# ESP32C5_RADIO register map
Vendor: Espressif; Series: ESP32-C5; File version: 0.1
Registers are 32-bit, read-write, no defined reset value unless marked. A register's access mark holds for its fields unless they carry their own. Offsets are from the block's base; [hi:lo] are bit positions; {n}, {i} and the like mark numbered series.

## WIFI_MAC_TX_COMMON — Shared Wi-Fi CCA, timeout and completion state used by MAC transmit queues and the PHY-owned Wi-Fi CCA gate.
Base 0x600A4C5C
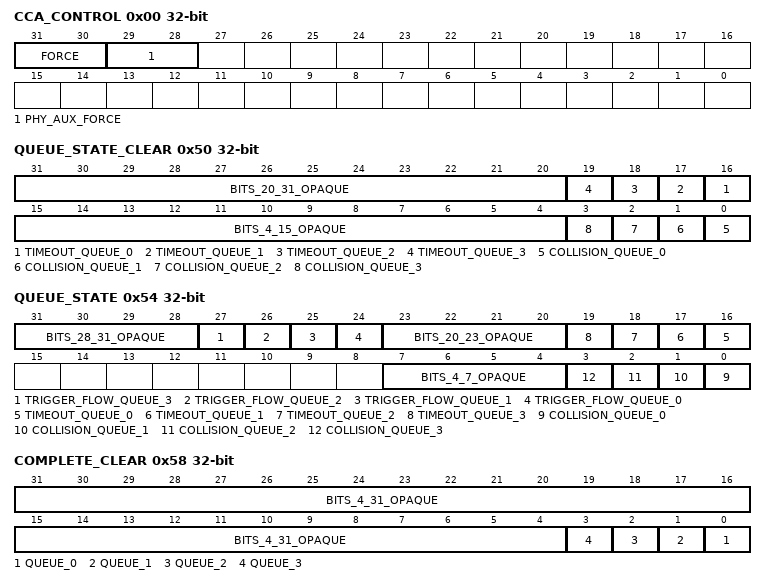
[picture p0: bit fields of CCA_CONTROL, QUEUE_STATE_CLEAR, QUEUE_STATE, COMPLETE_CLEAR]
0x00 CCA_CONTROL — Project-assigned name. Global Wi-Fi TX CCA control; complete PHY enable/disable leaves update the high two fields through separate fresh reads.
  [31:30] FORCE — Project-assigned name. Value three suppresses CCA while invalidating a timed-out queue. Complete libphy[phy_reg.o]::phy_disable_cca writes encoding two and complete libphy[phy_reg.o]::phy_enable_cca writes zero.
  [29:28] PHY_AUX_FORCE — Project-assigned name. Complete libphy[phy_reg.o]::phy_disable_cca writes encoding two and complete libphy[phy_reg.o]::phy_enable_cca writes zero in their second fresh-read edge.
0x50 QUEUE_STATE_CLEAR wo write-1-clears — Project-assigned name. Queue collision/timeout state acknowledgement.
  [31:20] BITS_20_31_OPAQUE — Opaque: meaning not established.
  [n+16] TIMEOUT_QUEUE_{n} (n=0..3) — Project-assigned name.
  [15:4] BITS_4_15_OPAQUE — Opaque: meaning not established.
  [n] COLLISION_QUEUE_{n} (n=0..3) — Project-assigned name.
0x54 QUEUE_STATE ro — Project-assigned name. Per-queue timeout and trigger-flow state. The complete trigger-flow HAL getter returns the entire high byte; the complete completion dispatcher then right-shifts it by the completed queue number and tests bit zero.
  [31:28] BITS_28_31_OPAQUE — Opaque: meaning not established. The complete HAL returns four additional high bitmap bits whose bounded ordinary-queue meaning remains unresolved.
  [27] TRIGGER_FLOW_QUEUE_3 — Project-assigned name.
  [26] TRIGGER_FLOW_QUEUE_2 — Project-assigned name.
  [25] TRIGGER_FLOW_QUEUE_1 — Project-assigned name.
  [24] TRIGGER_FLOW_QUEUE_0 — Project-assigned name. Queue zero is participating in the hardware Trigger-based transmit flow.
  [23:20] BITS_20_23_OPAQUE — Opaque: meaning not established.
  [n+16] TIMEOUT_QUEUE_{n} (n=0..3) — Project-assigned name.
  [7:4] BITS_4_7_OPAQUE — Opaque: meaning not established. Observed source use; the individual hardware meaning is unknown.
  [n] COLLISION_QUEUE_{n} (n=0..3) — Project-assigned name.
0x58 COMPLETE_CLEAR write-1-clears — Project-assigned name. Preserved-image acknowledgement for ordinary queue completion bits.
  [31:4] BITS_4_31_OPAQUE — Opaque: meaning not established.
  [n] QUEUE_{n} (n=0..3) — Project-assigned name.
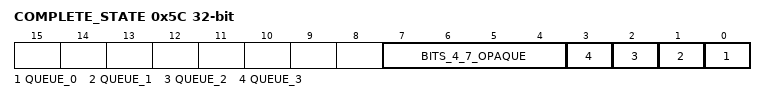
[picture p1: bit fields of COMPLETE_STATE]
0x5C COMPLETE_STATE ro — Project-assigned name. Low four bits report completed ordinary queues 0..3.
  [7:4] BITS_4_7_OPAQUE — Opaque: meaning not established. Observed source use; the individual hardware meaning is unknown.
  [n] QUEUE_{n} (n=0..3) — Project-assigned name.

## WIFI_MAC_ERSU_ACK_RATE — Four byte lanes independently replaced by hal_he_set_ersu_ack_rate; no bit-level rate encoding is assigned. SOURCE: C5_LIBPP_ROM_ERSU_ACK_RATE.
Base 0x600A4404
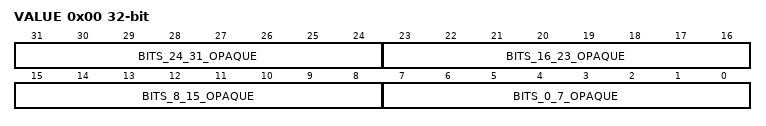
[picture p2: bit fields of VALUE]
0x00 VALUE — Project-assigned name. Four ordered fresh-read byte replacements at +0, +8, +16 and +24 bits. Each publishes 0x80 or 0xa0 while preserving the other three bytes.
  [31:24] BITS_24_31_OPAQUE — Opaque: meaning not established. Byte lane 3 explicitly replaced by complete hal_he_set_ersu_ack_rate; inner encoding unknown. SOURCE: C5_LIBPP_ROM_ERSU_ACK_RATE.
  [23:16] BITS_16_23_OPAQUE — Opaque: meaning not established. Byte lane 2 explicitly replaced by complete hal_he_set_ersu_ack_rate; inner encoding unknown. SOURCE: C5_LIBPP_ROM_ERSU_ACK_RATE.
  [15:8] BITS_8_15_OPAQUE — Opaque: meaning not established. Byte lane 1 explicitly replaced by complete hal_he_set_ersu_ack_rate; inner encoding unknown. SOURCE: C5_LIBPP_ROM_ERSU_ACK_RATE.
  [7:0] BITS_0_7_OPAQUE — Opaque: meaning not established. Byte lane 0 explicitly replaced by complete hal_he_set_ersu_ack_rate; inner encoding unknown. SOURCE: C5_LIBPP_ROM_ERSU_ACK_RATE.
